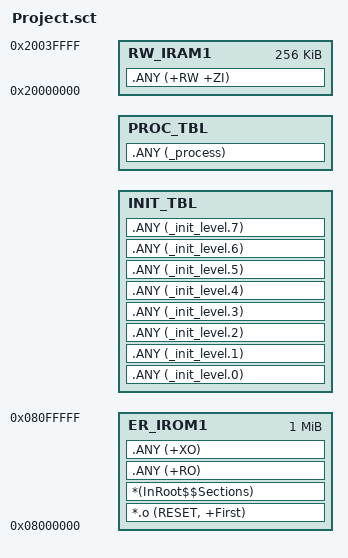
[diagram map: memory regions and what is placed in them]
; *************************************************************
; *** Scatter-Loading Description File generated by uVision ***
; *************************************************************

LR_IROM1 0x08000000 0x00100000  {    ; load region size_region
  ER_IROM1 0x08000000 0x00100000  {  ; load address = execution address
   *.o (RESET, +First)
   *(InRoot$$Sections)
   .ANY (+RO)
   .ANY (+XO)
  }
  INIT_TBL +0 {
    .ANY (_init_level.0)
    .ANY (_init_level.1)
    .ANY (_init_level.2)
    .ANY (_init_level.3)
    .ANY (_init_level.4)
    .ANY (_init_level.5)
    .ANY (_init_level.6)
    .ANY (_init_level.7)
  }
  PROC_TBL +0 {
    .ANY (_process)
  }
  RW_IRAM1 0x20000000 0x00040000  {  ; RW data
   .ANY (+RW +ZI)
  }
}

